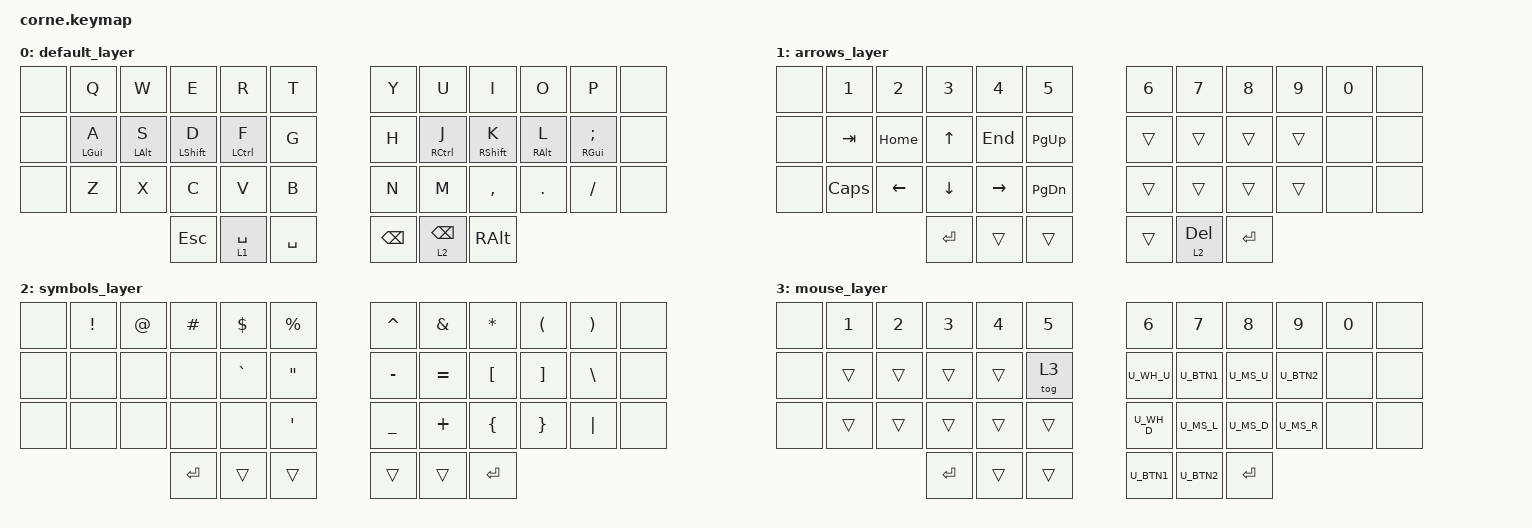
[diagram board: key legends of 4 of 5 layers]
/*
 * Copyright (c) 2020 The ZMK Contributors
 *
 * SPDX-License-Identifier: MIT
 */

#include <dt-bindings/zmk/keys.h>
#include <dt-bindings/zmk/bt.h>
#include <behaviors.dtsi>
#include "mouse.dtsi"

/ {
    behaviours {
        hm: homerow_mods {
            compatible = "zmk,behavior-hold-tap";
            label = "HOMEROW_MODS";
            #binding-cells = <2>;
            tapping-term-ms = <160>;
            quick-tap-ms = <0>;
            flavor = "tap-preferred";
            bindings = <&kp>, <&kp>;
        };
    };

    conditional_layers {
        compatible = "zmk,conditional-layers";
        tri_layer {
            if-layers = <1 2>;
            then-layer = <4>;
        };
    };

    keymap {
        compatible = "zmk,keymap";

        default_layer {
            bindings = <
            &none &kp Q &kp W &kp E &kp R &kp T &kp Y &kp U &kp I &kp O &kp P &none
            &none &hm LGUI A &hm LALT S &hm LSHIFT D &hm LCTRL F &kp G &kp H &hm RCTRL J &hm RSHIFT K &hm RALT L &hm RGUI SEMICOLON &none
            &none &kp Z &kp X &kp C &kp V &kp B &kp N &kp M &kp COMMA &kp PERIOD &kp SLASH &none
            &kp ESCAPE &lt 1 SPACE &kp SPACE &kp BACKSPACE &lt 2 BACKSPACE &kp RALT
            >;
        };
        arrows_layer {
            bindings = <
            &none &kp NUMBER_1 &kp NUMBER_2 &kp NUMBER_3 &kp NUMBER_4 &kp NUMBER_5 &kp NUMBER_6 &kp NUMBER_7 &kp NUMBER_8 &kp NUMBER_9 &kp NUMBER_0 &none
            &none &kp TAB  &kp HOME &kp UP   &kp END   &kp PG_UP &trans &trans &trans &trans &none &none
            &none &kp CAPS &kp LEFT &kp DOWN &kp RIGHT &kp PG_DN &trans &trans &trans &trans &none &none
            &kp ENTER &trans &trans &trans &lt 2 DEL &kp ENTER
            >;
        };
        symbols_layer {
            bindings = <
            &none &kp EXCLAMATION &kp AT_SIGN &kp HASH &kp DOLLAR &kp PERCENT &kp CARET &kp AMPERSAND &kp ASTERISK &kp LEFT_PARENTHESIS &kp RIGHT_PARENTHESIS &none
            &none &none &none &none &kp GRAVE &kp DOUBLE_QUOTES &kp MINUS &kp EQUAL &kp LEFT_BRACKET &kp RIGHT_BRACKET &kp BACKSLASH &none
            &none &none &none &none &none &kp SINGLE_QUOTE &kp UNDERSCORE &kp PLUS &kp LEFT_BRACE &kp RIGHT_BRACE &kp PIPE &none
            &kp ENTER &trans &trans &trans &trans &kp ENTER
            >;
        };
        mouse_layer {
            bindings = <
            &none &kp NUMBER_1 &kp NUMBER_2 &kp NUMBER_3 &kp NUMBER_4 &kp NUMBER_5 &kp NUMBER_6 &kp NUMBER_7 &kp NUMBER_8 &kp NUMBER_9 &kp NUMBER_0 &none
            &none &trans &trans &trans &trans &tog 3  U_WH_U U_BTN1 U_MS_U U_BTN2 &none &none
            &none &trans &trans &trans &trans &trans  U_WH_D U_MS_L U_MS_D U_MS_R &none &none
            &kp ENTER &trans &trans U_BTN1 U_BTN2 &kp ENTER
            >;
        };
        bt_layer {
            bindings = <
                &none &bt BT_PRV &bt BT_NXT &none &none &bt BT_CLR &none &none &none &none &none
                &none &kp C_VOL_UP &kp C_BRI_UP &none &tog 3 &none &none &none &none &none &none &none
                &none &kp C_VOL_DN &kp C_BRI_DN &none &none &none &none &none &none &none &none &none
                &none &none &none &none &none &none 
            >;
        };
    };
};
